# TM4C129XKCZAD register map
Vendor: Texas Instruments; Series: TM4C; File version: 12591
CPU: CM4 r1p2, little endian, no MPU, FPU, 3 interrupt priority bits
Registers are 32-bit, read-write, no defined reset value unless marked. A register's access mark holds for its fields unless they carry their own. Offsets are from the block's base; [hi:lo] are bit positions; {n}, {i} and the like mark numbered series.

## SYSCTL — Register map for SYSCTL peripheral
Base 0x400FE000; register names take the prefix SYSCTL
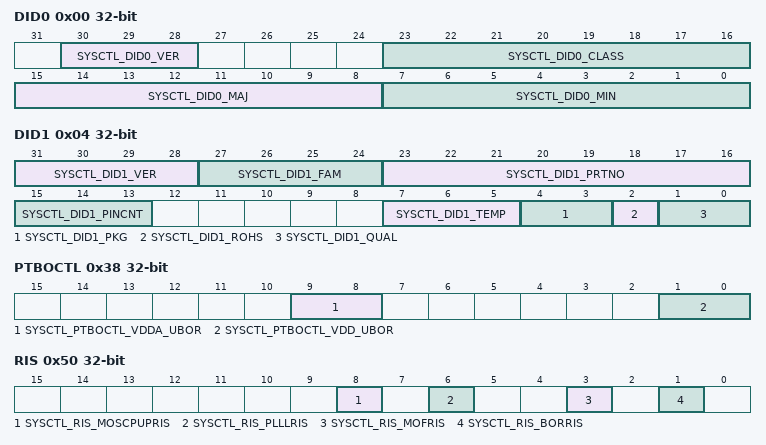
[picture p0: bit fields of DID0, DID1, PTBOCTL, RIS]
0x00 DID0 — Device Identification 0
  [30:28] SYSCTL_DID0_VER — DID0 Version
    1=Second version of the DID0 register format
  [23:16] SYSCTL_DID0_CLASS — Device Class
    10=SYSCTL_DID0_CLASS_TM4C129 (Tiva(TM) TM4C129-class microcontrollers)
  [15:8] SYSCTL_DID0_MAJ — Major Revision
    0=SYSCTL_DID0_MAJ_REVA (Revision A (initial device)); 1=SYSCTL_DID0_MAJ_REVB (Revision B (first base layer revision)); 2=SYSCTL_DID0_MAJ_REVC (Revision C (second base layer revision))
  [7:0] SYSCTL_DID0_MIN — Minor Revision
    0=Initial device, or a major revision update; 1=First metal layer change; 2=Second metal layer change
0x04 DID1 — Device Identification 1
  [31:28] SYSCTL_DID1_VER — DID1 Version
  [27:24] SYSCTL_DID1_FAM — Family
  [23:16] SYSCTL_DID1_PRTNO — Part Number
  [15:13] SYSCTL_DID1_PINCNT — Package Pin Count
    2=100-pin LQFP package; 3=64-pin LQFP package; 4=144-pin LQFP package; 5=157-pin BGA package; 6=128-pin TQFP package
  [7:5] SYSCTL_DID1_TEMP — Temperature Range
    0=SYSCTL_DID1_TEMP_C (Commercial temperature range); 1=SYSCTL_DID1_TEMP_I (Industrial temperature range); 2=SYSCTL_DID1_TEMP_E (Extended temperature range)
  [4:3] SYSCTL_DID1_PKG — Package Type
    1=SYSCTL_DID1_PKG_QFP (QFP package); 2=SYSCTL_DID1_PKG_BGA (BGA package)
  [2] SYSCTL_DID1_ROHS — RoHS-Compliance
  [1:0] SYSCTL_DID1_QUAL — Qualification Status
    0=SYSCTL_DID1_QUAL_ES (Engineering Sample (unqualified)); 1=SYSCTL_DID1_QUAL_PP (Pilot Production (unqualified)); 2=SYSCTL_DID1_QUAL_FQ (Fully Qualified)
0x38 PTBOCTL — Power-Temp Brown Out Control
  [9:8] SYSCTL_PTBOCTL_VDDA_UBOR — VDDA under BOR Event Action
    0=SYSCTL_PTBOCTL_VDDA_UBOR_NONE (No Action); 1=SYSCTL_PTBOCTL_VDDA_UBOR_SYSINT (System control interrupt); 2=SYSCTL_PTBOCTL_VDDA_UBOR_NMI (NMI); 3=SYSCTL_PTBOCTL_VDDA_UBOR_RST (Reset)
  [1:0] SYSCTL_PTBOCTL_VDD_UBOR — VDD (VDDS) under BOR Event Action
    0=SYSCTL_PTBOCTL_VDD_UBOR_NONE (No Action); 1=SYSCTL_PTBOCTL_VDD_UBOR_SYSINT (System control interrupt); 2=SYSCTL_PTBOCTL_VDD_UBOR_NMI (NMI); 3=SYSCTL_PTBOCTL_VDD_UBOR_RST (Reset)
0x50 RIS — Raw Interrupt Status
  [8] SYSCTL_RIS_MOSCPUPRIS — MOSC Power Up Raw Interrupt Status
  [6] SYSCTL_RIS_PLLLRIS — PLL Lock Raw Interrupt Status
  [3] SYSCTL_RIS_MOFRIS — Main Oscillator Failure Raw Interrupt Status
  [1] SYSCTL_RIS_BORRIS — Brown-Out Reset Raw Interrupt Status
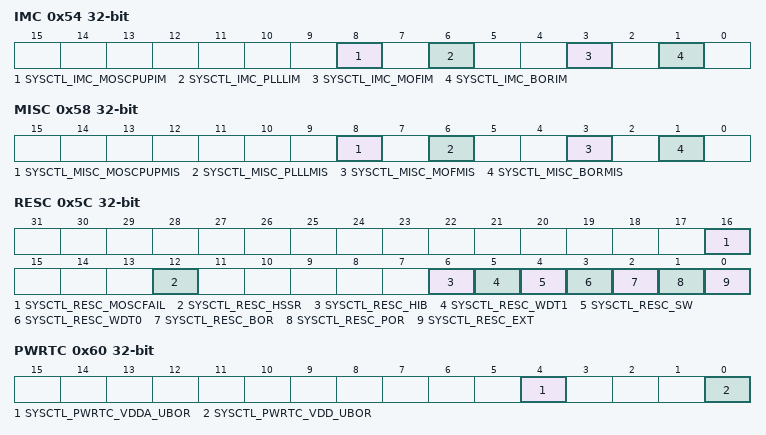
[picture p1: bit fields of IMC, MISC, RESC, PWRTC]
0x54 IMC — Interrupt Mask Control
  [8] SYSCTL_IMC_MOSCPUPIM — MOSC Power Up Interrupt Mask
  [6] SYSCTL_IMC_PLLLIM — PLL Lock Interrupt Mask
  [3] SYSCTL_IMC_MOFIM — Main Oscillator Failure Interrupt Mask
  [1] SYSCTL_IMC_BORIM — Brown-Out Reset Interrupt Mask
0x58 MISC — Masked Interrupt Status and Clear
  [8] SYSCTL_MISC_MOSCPUPMIS — MOSC Power Up Masked Interrupt Status
  [6] SYSCTL_MISC_PLLLMIS — PLL Lock Masked Interrupt Status
  [3] SYSCTL_MISC_MOFMIS — Main Oscillator Failure Masked Interrupt Status
  [1] SYSCTL_MISC_BORMIS — BOR Masked Interrupt Status
0x5C RESC — Reset Cause
  [16] SYSCTL_RESC_MOSCFAIL — MOSC Failure Reset
  [12] SYSCTL_RESC_HSSR — HSSR Reset
  [6] SYSCTL_RESC_HIB — HIB Reset
  [5] SYSCTL_RESC_WDT1 — Watchdog Timer 1 Reset
  [4] SYSCTL_RESC_SW — Software Reset
  [3] SYSCTL_RESC_WDT0 — Watchdog Timer 0 Reset
  [2] SYSCTL_RESC_BOR — Brown-Out Reset
  [1] SYSCTL_RESC_POR — Power-On Reset
  [0] SYSCTL_RESC_EXT — External Reset
0x60 PWRTC — Power-Temperature Cause
  [4] SYSCTL_PWRTC_VDDA_UBOR — VDDA Under BOR Status
  [0] SYSCTL_PWRTC_VDD_UBOR — VDD Under BOR Status
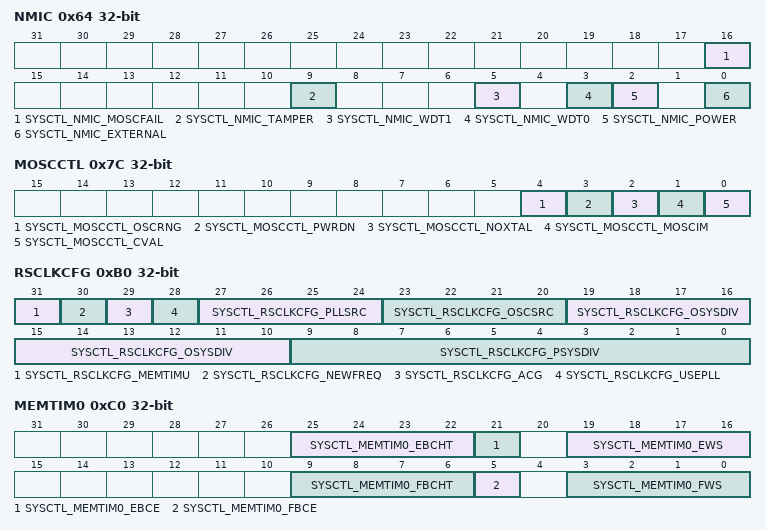
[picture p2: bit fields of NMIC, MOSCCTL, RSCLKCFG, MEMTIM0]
0x64 NMIC — NMI Cause Register
  [16] SYSCTL_NMIC_MOSCFAIL — MOSC Failure NMI
  [9] SYSCTL_NMIC_TAMPER — Tamper Event NMI
  [5] SYSCTL_NMIC_WDT1 — Watch Dog Timer (WDT) 1 NMI
  [3] SYSCTL_NMIC_WDT0 — Watch Dog Timer (WDT) 0 NMI
  [2] SYSCTL_NMIC_POWER — Power/Brown Out Event NMI
  [0] SYSCTL_NMIC_EXTERNAL — External Pin NMI
0x7C MOSCCTL — Main Oscillator Control
  [4] SYSCTL_MOSCCTL_OSCRNG — Oscillator Range
  [3] SYSCTL_MOSCCTL_PWRDN — Power Down
  [2] SYSCTL_MOSCCTL_NOXTAL — No Crystal Connected
  [1] SYSCTL_MOSCCTL_MOSCIM — MOSC Failure Action
  [0] SYSCTL_MOSCCTL_CVAL — Clock Validation for MOSC
0xB0 RSCLKCFG — Run and Sleep Mode Configuration Register
  [31] SYSCTL_RSCLKCFG_MEMTIMU — Memory Timing Register Update
  [30] SYSCTL_RSCLKCFG_NEWFREQ — New PLLFREQ Accept
  [29] SYSCTL_RSCLKCFG_ACG — Auto Clock Gating
  [28] SYSCTL_RSCLKCFG_USEPLL — Use PLL
  [27:24] SYSCTL_RSCLKCFG_PLLSRC — PLL Source
    0=SYSCTL_RSCLKCFG_PLLSRC_PIOSC (PIOSC is PLL input clock source); 3=SYSCTL_RSCLKCFG_PLLSRC_MOSC (MOSC is the PLL input clock source)
  [23:20] SYSCTL_RSCLKCFG_OSCSRC — Oscillator Source
    0=SYSCTL_RSCLKCFG_OSCSRC_PIOSC (PIOSC is oscillator source); 2=SYSCTL_RSCLKCFG_OSCSRC_LFIOSC (LFIOSC is oscillator source); 3=SYSCTL_RSCLKCFG_OSCSRC_MOSC (MOSC is oscillator source); 4=SYSCTL_RSCLKCFG_OSCSRC_RTC (Hibernation Module RTC Oscillator (RTCOSC))
  [19:10] SYSCTL_RSCLKCFG_OSYSDIV — Oscillator System Clock Divisor
  [9:0] SYSCTL_RSCLKCFG_PSYSDIV — PLL System Clock Divisor
0xC0 MEMTIM0 — Memory Timing Parameter Register 0 for Main Flash and EEPROM
  [25:22] SYSCTL_MEMTIM0_EBCHT — EEPROM Clock High Time
    0=SYSCTL_MEMTIM0_EBCHT_0_5 (1/2 system clock period); 1=1 system clock period; 2=SYSCTL_MEMTIM0_EBCHT_1_5 (1.5 system clock periods); 3=2 system clock periods; 4=SYSCTL_MEMTIM0_EBCHT_2_5 (2.5 system clock periods); 5=3 system clock periods; 6=SYSCTL_MEMTIM0_EBCHT_3_5 (3.5 system clock periods); 7=4 system clock periods; 8=SYSCTL_MEMTIM0_EBCHT_4_5 (4.5 system clock periods)
  [21] SYSCTL_MEMTIM0_EBCE — EEPROM Bank Clock Edge
  [19:16] SYSCTL_MEMTIM0_EWS — EEPROM Wait States
  [9:6] SYSCTL_MEMTIM0_FBCHT — Flash Bank Clock High Time
    0=SYSCTL_MEMTIM0_FBCHT_0_5 (1/2 system clock period); 1=1 system clock period; 2=SYSCTL_MEMTIM0_FBCHT_1_5 (1.5 system clock periods); 3=2 system clock periods; 4=SYSCTL_MEMTIM0_FBCHT_2_5 (2.5 system clock periods); 5=3 system clock periods; 6=SYSCTL_MEMTIM0_FBCHT_3_5 (3.5 system clock periods); 7=4 system clock periods; 8=SYSCTL_MEMTIM0_FBCHT_4_5 (4.5 system clock periods)
  [5] SYSCTL_MEMTIM0_FBCE — Flash Bank Clock Edge
  [3:0] SYSCTL_MEMTIM0_FWS — Flash Wait State
0x138 ALTCLKCFG — Alternate Clock Configuration
  [3:0] SYSCTL_ALTCLKCFG_ALTCLK — Alternate Clock Source
    0=SYSCTL_ALTCLKCFG_ALTCLK_PIOSC (PIOSC); 3=SYSCTL_ALTCLKCFG_ALTCLK_RTCOSC (Hibernation Module Real-time clock output (RTCOSC)); 4=SYSCTL_ALTCLKCFG_ALTCLK_LFIOSC (Low-frequency internal oscillator (LFIOSC))
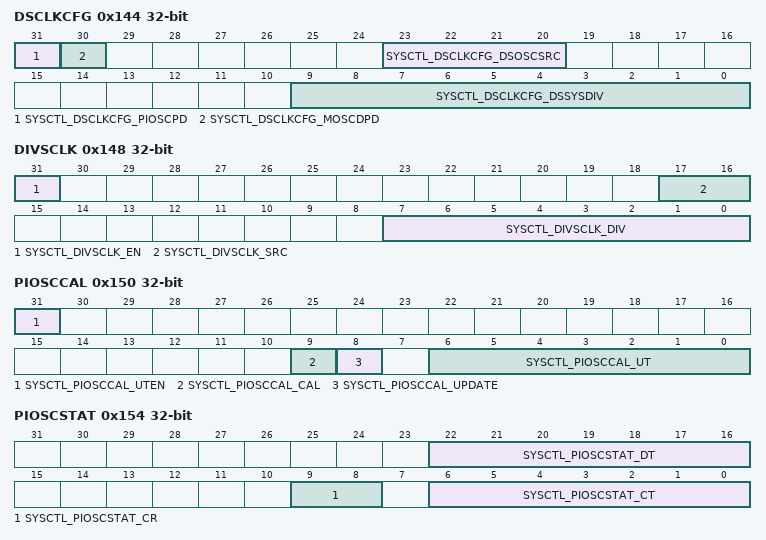
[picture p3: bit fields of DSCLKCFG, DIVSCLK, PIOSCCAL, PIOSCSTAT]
0x144 DSCLKCFG — Deep Sleep Clock Configuration Register
  [31] SYSCTL_DSCLKCFG_PIOSCPD — PIOSC Power Down
  [30] SYSCTL_DSCLKCFG_MOSCDPD — MOSC Disable Power Down
  [23:20] SYSCTL_DSCLKCFG_DSOSCSRC — Deep Sleep Oscillator Source
    0=SYSCTL_DSCLKCFG_DSOSCSRC_PIOSC (PIOSC); 2=SYSCTL_DSCLKCFG_DSOSCSRC_LFIOSC (LFIOSC); 3=SYSCTL_DSCLKCFG_DSOSCSRC_MOSC (MOSC); 4=SYSCTL_DSCLKCFG_DSOSCSRC_RTC (Hibernation Module RTCOSC)
  [9:0] SYSCTL_DSCLKCFG_DSSYSDIV — Deep Sleep Clock Divisor
0x148 DIVSCLK — Divisor and Source Clock Configuration
  [31] SYSCTL_DIVSCLK_EN — DIVSCLK Enable
  [17:16] SYSCTL_DIVSCLK_SRC — Clock Source
    0=SYSCTL_DIVSCLK_SRC_SYSCLK (System Clock); 1=SYSCTL_DIVSCLK_SRC_PIOSC (PIOSC); 2=SYSCTL_DIVSCLK_SRC_MOSC (MOSC)
  [7:0] SYSCTL_DIVSCLK_DIV — Divisor Value
0x14C SYSPROP — System Properties
  [0] SYSCTL_SYSPROP_FPU — FPU Present
0x150 PIOSCCAL — Precision Internal Oscillator Calibration
  [31] SYSCTL_PIOSCCAL_UTEN — Use User Trim Value
  [9] SYSCTL_PIOSCCAL_CAL — Start Calibration
  [8] SYSCTL_PIOSCCAL_UPDATE — Update Trim
  [6:0] SYSCTL_PIOSCCAL_UT — User Trim Value
0x154 PIOSCSTAT — Precision Internal Oscillator Statistics
  [22:16] SYSCTL_PIOSCSTAT_DT — Default Trim Value
  [9:8] SYSCTL_PIOSCSTAT_CR — Calibration Result
    0=SYSCTL_PIOSCSTAT_CRNONE (Calibration has not been attempted); 1=SYSCTL_PIOSCSTAT_CRPASS (The last calibration operation completed to meet 1% accuracy); 2=SYSCTL_PIOSCSTAT_CRFAIL (The last calibration operation failed to meet 1% accuracy)
  [6:0] SYSCTL_PIOSCSTAT_CT — Calibration Trim Value
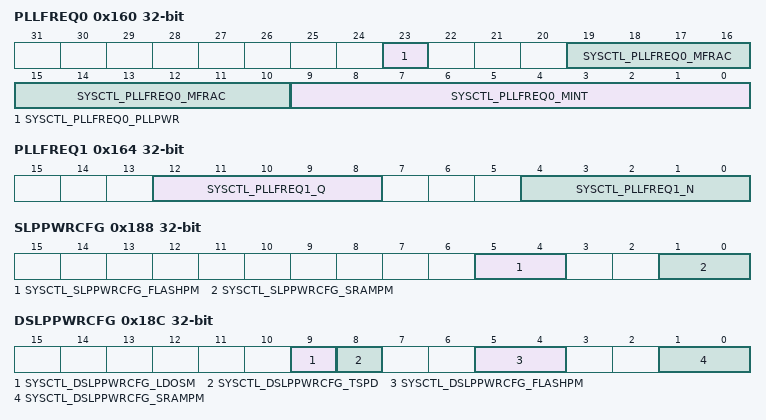
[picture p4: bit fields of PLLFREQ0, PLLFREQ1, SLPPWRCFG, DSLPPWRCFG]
0x160 PLLFREQ0 — PLL Frequency 0
  [23] SYSCTL_PLLFREQ0_PLLPWR — PLL Power
  [19:10] SYSCTL_PLLFREQ0_MFRAC — PLL M Fractional Value
  [9:0] SYSCTL_PLLFREQ0_MINT — PLL M Integer Value
0x164 PLLFREQ1 — PLL Frequency 1
  [12:8] SYSCTL_PLLFREQ1_Q — PLL Q Value
  [4:0] SYSCTL_PLLFREQ1_N — PLL N Value
0x168 PLLSTAT — PLL Status
  [0] SYSCTL_PLLSTAT_LOCK — PLL Lock
0x188 SLPPWRCFG — Sleep Power Configuration
  [5:4] SYSCTL_SLPPWRCFG_FLASHPM — Flash Power Modes
    0=SYSCTL_SLPPWRCFG_FLASHPM_NRM (Active Mode); 2=SYSCTL_SLPPWRCFG_FLASHPM_SLP (Low Power Mode)
  [1:0] SYSCTL_SLPPWRCFG_SRAMPM — SRAM Power Modes
    0=SYSCTL_SLPPWRCFG_SRAMPM_NRM (Active Mode); 1=SYSCTL_SLPPWRCFG_SRAMPM_SBY (Standby Mode); 3=SYSCTL_SLPPWRCFG_SRAMPM_LP (Low Power Mode)
0x18C DSLPPWRCFG — Deep-Sleep Power Configuration
  [9] SYSCTL_DSLPPWRCFG_LDOSM — LDO Sleep Mode
  [8] SYSCTL_DSLPPWRCFG_TSPD — Temperature Sense Power Down
  [5:4] SYSCTL_DSLPPWRCFG_FLASHPM — Flash Power Modes
    0=SYSCTL_DSLPPWRCFG_FLASHPM_NRM (Active Mode); 2=SYSCTL_DSLPPWRCFG_FLASHPM_SLP (Low Power Mode)
  [1:0] SYSCTL_DSLPPWRCFG_SRAMPM — SRAM Power Modes
    0=SYSCTL_DSLPPWRCFG_SRAMPM_NRM (Active Mode); 1=SYSCTL_DSLPPWRCFG_SRAMPM_SBY (Standby Mode); 3=SYSCTL_DSLPPWRCFG_SRAMPM_LP (Low Power Mode)
0x1A0 NVMSTAT — Non-Volatile Memory Information
  [0] SYSCTL_NVMSTAT_FWB — 32 Word Flash Write Buffer Available
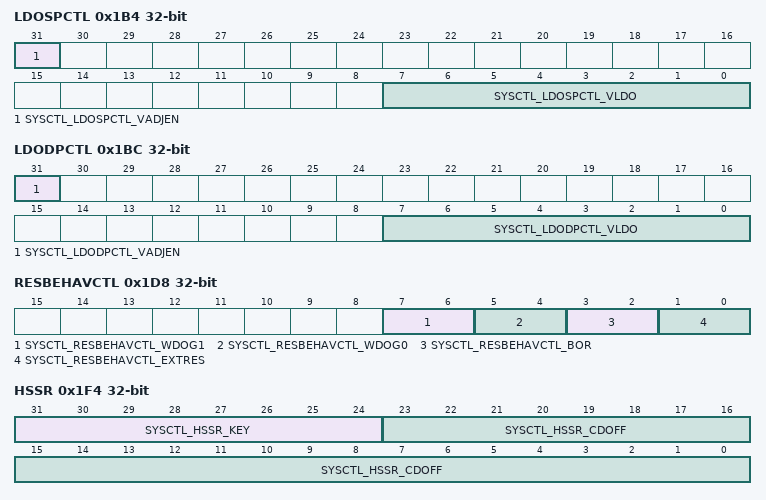
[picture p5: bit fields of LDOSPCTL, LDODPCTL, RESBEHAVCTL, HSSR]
0x1B4 LDOSPCTL — LDO Sleep Power Control
  [31] SYSCTL_LDOSPCTL_VADJEN — Voltage Adjust Enable
  [7:0] SYSCTL_LDOSPCTL_VLDO — LDO Output Voltage
    18=SYSCTL_LDOSPCTL_VLDO_0_90V (0.90 V); 19=SYSCTL_LDOSPCTL_VLDO_0_95V (0.95 V); 20=SYSCTL_LDOSPCTL_VLDO_1_00V (1.00 V); 21=SYSCTL_LDOSPCTL_VLDO_1_05V (1.05 V); 22=SYSCTL_LDOSPCTL_VLDO_1_10V (1.10 V); 23=SYSCTL_LDOSPCTL_VLDO_1_15V (1.15 V); 24=SYSCTL_LDOSPCTL_VLDO_1_20V (1.20 V)
0x1BC LDODPCTL — LDO Deep-Sleep Power Control
  [31] SYSCTL_LDODPCTL_VADJEN — Voltage Adjust Enable
  [7:0] SYSCTL_LDODPCTL_VLDO — LDO Output Voltage
    18=SYSCTL_LDODPCTL_VLDO_0_90V (0.90 V); 19=SYSCTL_LDODPCTL_VLDO_0_95V (0.95 V); 20=SYSCTL_LDODPCTL_VLDO_1_00V (1.00 V); 21=SYSCTL_LDODPCTL_VLDO_1_05V (1.05 V); 22=SYSCTL_LDODPCTL_VLDO_1_10V (1.10 V); 23=SYSCTL_LDODPCTL_VLDO_1_15V (1.15 V); 24=SYSCTL_LDODPCTL_VLDO_1_20V (1.20 V); 25=SYSCTL_LDODPCTL_VLDO_1_25V (1.25 V); 26=SYSCTL_LDODPCTL_VLDO_1_30V (1.30 V); 27=SYSCTL_LDODPCTL_VLDO_1_35V (1.35 V)
0x1D8 RESBEHAVCTL — Reset Behavior Control Register
  [7:6] SYSCTL_RESBEHAVCTL_WDOG1 — Watchdog 1 Reset Operation
    2=SYSCTL_RESBEHAVCTL_WDOG1_SYSRST (Watchdog 1 issues a system reset. The application starts within 10 us); 3=SYSCTL_RESBEHAVCTL_WDOG1_POR (Watchdog 1 issues a simulated POR sequence. Application starts less than 500 us after deassertion (Default))
  [5:4] SYSCTL_RESBEHAVCTL_WDOG0 — Watchdog 0 Reset Operation
    2=SYSCTL_RESBEHAVCTL_WDOG0_SYSRST (Watchdog 0 issues a system reset. The application starts within 10 us); 3=SYSCTL_RESBEHAVCTL_WDOG0_POR (Watchdog 0 issues a simulated POR sequence. Application starts less than 500 us after deassertion (Default))
  [3:2] SYSCTL_RESBEHAVCTL_BOR — BOR Reset operation
    2=SYSCTL_RESBEHAVCTL_BOR_SYSRST (Brown Out Reset issues system reset. The application starts within 10 us); 3=SYSCTL_RESBEHAVCTL_BOR_POR (Brown Out Reset issues a simulated POR sequence. The application starts less than 500 us after deassertion (Default))
  [1:0] SYSCTL_RESBEHAVCTL_EXTRES — External RST Pin Operation
    2=SYSCTL_RESBEHAVCTL_EXTRES_SYSRST (External RST assertion issues a system reset. The application starts within 10 us); 3=SYSCTL_RESBEHAVCTL_EXTRES_POR (External RST assertion issues a simulated POR sequence. Application starts less than 500 us after deassertion (Default))
0x1F4 HSSR — Hardware System Service Request
  [31:24] SYSCTL_HSSR_KEY — Write Key
  [23:0] SYSCTL_HSSR_CDOFF — Command Descriptor Pointer
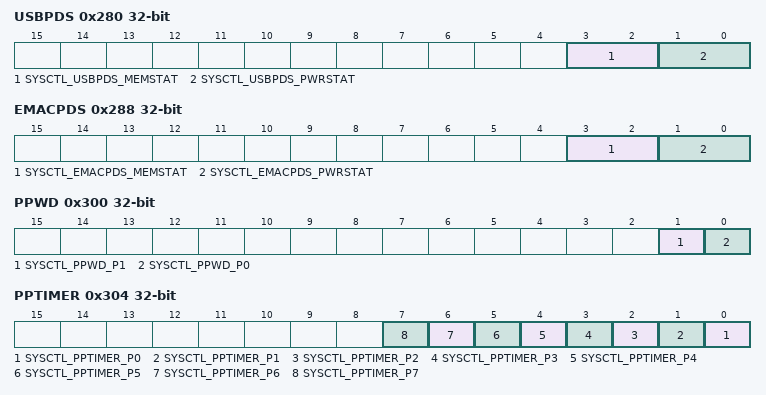
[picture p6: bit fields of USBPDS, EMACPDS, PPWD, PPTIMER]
0x280 USBPDS — USB Power Domain Status
  [3:2] SYSCTL_USBPDS_MEMSTAT — Memory Array Power Status
    0=SYSCTL_USBPDS_MEMSTAT_OFF (Array OFF); 1=SYSCTL_USBPDS_MEMSTAT_RETAIN (SRAM Retention); 3=SYSCTL_USBPDS_MEMSTAT_ON (Array On)
  [1:0] SYSCTL_USBPDS_PWRSTAT — Power Domain Status
    0=SYSCTL_USBPDS_PWRSTAT_OFF (OFF); 3=SYSCTL_USBPDS_PWRSTAT_ON (ON)
0x284 USBMPC — USB Memory Power Control
  [1:0] SYSCTL_USBMPC_PWRCTL — Memory Array Power Control
    0=SYSCTL_USBMPC_PWRCTL_OFF (Array OFF); 1=SYSCTL_USBMPC_PWRCTL_RETAIN (SRAM Retention); 3=SYSCTL_USBMPC_PWRCTL_ON (Array On)
0x288 EMACPDS — Ethernet MAC Power Domain Status
  [3:2] SYSCTL_EMACPDS_MEMSTAT — Memory Array Power Status
    0=SYSCTL_EMACPDS_MEMSTAT_OFF (Array OFF); 3=SYSCTL_EMACPDS_MEMSTAT_ON (Array On)
  [1:0] SYSCTL_EMACPDS_PWRSTAT — Power Domain Status
    0=SYSCTL_EMACPDS_PWRSTAT_OFF (OFF); 3=SYSCTL_EMACPDS_PWRSTAT_ON (ON)
0x28C EMACMPC — Ethernet MAC Memory Power Control
  [1:0] SYSCTL_EMACMPC_PWRCTL — Memory Array Power Control
    0=SYSCTL_EMACMPC_PWRCTL_OFF (Array OFF); 3=SYSCTL_EMACMPC_PWRCTL_ON (Array On)
0x294 LCDMPC — LCD Memory Power Control
  [1:0] SYSCTL_LCDMPC_PWRCTL — Memory Array Power Control
    0=SYSCTL_LCDMPC_PWRCTL_OFF (Array OFF); 3=SYSCTL_LCDMPC_PWRCTL_ON (Array On)
0x300 PPWD — Watchdog Timer Peripheral Present
  [1] SYSCTL_PPWD_P1 — Watchdog Timer 1 Present
  [0] SYSCTL_PPWD_P0 — Watchdog Timer 0 Present
0x304 PPTIMER — 16/32-Bit General-Purpose Timer Peripheral Present
  [n] SYSCTL_PPTIMER_P{n} (n=0..7) — 16/32-Bit General-Purpose Timer {n} Present
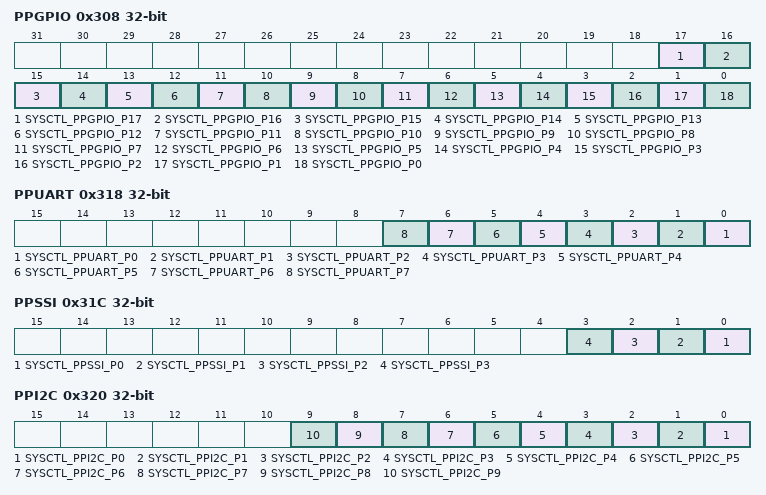
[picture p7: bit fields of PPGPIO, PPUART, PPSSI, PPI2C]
0x308 PPGPIO — General-Purpose Input/Output Peripheral Present
  [17] SYSCTL_PPGPIO_P17 — GPIO Port T Present
  [16] SYSCTL_PPGPIO_P16 — GPIO Port S Present
  [15] SYSCTL_PPGPIO_P15 — GPIO Port R Present
  [14] SYSCTL_PPGPIO_P14 — GPIO Port Q Present
  [13] SYSCTL_PPGPIO_P13 — GPIO Port P Present
  [12] SYSCTL_PPGPIO_P12 — GPIO Port N Present
  [11] SYSCTL_PPGPIO_P11 — GPIO Port M Present
  [10] SYSCTL_PPGPIO_P10 — GPIO Port L Present
  [9] SYSCTL_PPGPIO_P9 — GPIO Port K Present
  [8] SYSCTL_PPGPIO_P8 — GPIO Port J Present
  [7] SYSCTL_PPGPIO_P7 — GPIO Port H Present
  [6] SYSCTL_PPGPIO_P6 — GPIO Port G Present
  [5] SYSCTL_PPGPIO_P5 — GPIO Port F Present
  [4] SYSCTL_PPGPIO_P4 — GPIO Port E Present
  [3] SYSCTL_PPGPIO_P3 — GPIO Port D Present
  [2] SYSCTL_PPGPIO_P2 — GPIO Port C Present
  [1] SYSCTL_PPGPIO_P1 — GPIO Port B Present
  [0] SYSCTL_PPGPIO_P0 — GPIO Port A Present
0x30C PPDMA — Micro Direct Memory Access Peripheral Present
  [0] SYSCTL_PPDMA_P0 — uDMA Module Present
0x310 PPEPI — EPI Peripheral Present
  [0] SYSCTL_PPEPI_P0 — EPI Module Present
0x314 PPHIB — Hibernation Peripheral Present
  [0] SYSCTL_PPHIB_P0 — Hibernation Module Present
0x318 PPUART — Universal Asynchronous Receiver/Transmitter Peripheral Present
  [n] SYSCTL_PPUART_P{n} (n=0..7) — UART Module {n} Present
0x31C PPSSI — Synchronous Serial Interface Peripheral Present
  [n] SYSCTL_PPSSI_P{n} (n=0..3) — SSI Module {n} Present
0x320 PPI2C — Inter-Integrated Circuit Peripheral Present
  [n] SYSCTL_PPI2C_P{n} (n=0..9) — I2C Module {n} Present
0x328 PPUSB — Universal Serial Bus Peripheral Present
  [0] SYSCTL_PPUSB_P0 — USB Module Present
0x330 PPEPHY — Ethernet PHY Peripheral Present
  [0] SYSCTL_PPEPHY_P0 — Ethernet PHY Module Present
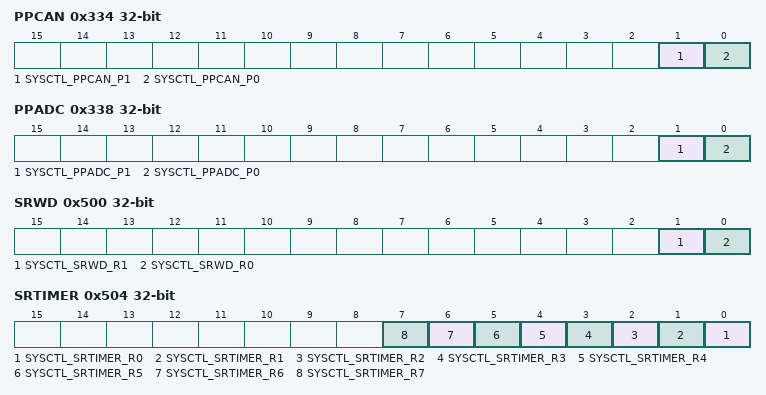
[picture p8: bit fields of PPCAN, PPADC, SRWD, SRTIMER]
0x334 PPCAN — Controller Area Network Peripheral Present
  [1] SYSCTL_PPCAN_P1 — CAN Module 1 Present
  [0] SYSCTL_PPCAN_P0 — CAN Module 0 Present
0x338 PPADC — Analog-to-Digital Converter Peripheral Present
  [1] SYSCTL_PPADC_P1 — ADC Module 1 Present
  [0] SYSCTL_PPADC_P0 — ADC Module 0 Present
0x33C PPACMP — Analog Comparator Peripheral Present
  [0] SYSCTL_PPACMP_P0 — Analog Comparator Module Present
0x340 PPPWM — Pulse Width Modulator Peripheral Present
  [0] SYSCTL_PPPWM_P0 — PWM Module 0 Present
0x344 PPQEI — Quadrature Encoder Interface Peripheral Present
  [0] SYSCTL_PPQEI_P0 — QEI Module 0 Present
0x348 PPLPC — Low Pin Count Interface Peripheral Present
  [0] SYSCTL_PPLPC_P0 — LPC Module Present
0x350 PPPECI — Platform Environment Control Interface Peripheral Present
  [0] SYSCTL_PPPECI_P0 — PECI Module Present
0x354 PPFAN — Fan Control Peripheral Present
  [0] SYSCTL_PPFAN_P0 — FAN Module 0 Present
0x358 PPEEPROM — EEPROM Peripheral Present
  [0] SYSCTL_PPEEPROM_P0 — EEPROM Module Present
0x35C PPWTIMER — 32/64-Bit Wide General-Purpose Timer Peripheral Present
  [0] SYSCTL_PPWTIMER_P0 — 32/64-Bit Wide General-Purpose Timer 0 Present
0x370 PPRTS — Remote Temperature Sensor Peripheral Present
  [0] SYSCTL_PPRTS_P0 — RTS Module Present
0x374 PPCCM — CRC and Cryptographic Modules Peripheral Present
  [0] SYSCTL_PPCCM_P0 — CRC and Cryptographic Modules Present
0x390 PPLCD — LCD Peripheral Present
  [0] SYSCTL_PPLCD_P0 — LCD Module Present
0x398 PPOWIRE — 1-Wire Peripheral Present
  [0] SYSCTL_PPOWIRE_P0 — 1-Wire Module Present
0x39C PPEMAC — Ethernet MAC Peripheral Present
  [0] SYSCTL_PPEMAC_P0 — Ethernet Controller Module Present
0x3A4 PPHIM — Human Interface Master Peripheral Present
  [0] SYSCTL_PPHIM_P0 — HIM Module Present
0x500 SRWD — Watchdog Timer Software Reset
  [1] SYSCTL_SRWD_R1 — Watchdog Timer 1 Software Reset
  [0] SYSCTL_SRWD_R0 — Watchdog Timer 0 Software Reset
0x504 SRTIMER — 16/32-Bit General-Purpose Timer Software Reset
  [n] SYSCTL_SRTIMER_R{n} (n=0..7) — 16/32-Bit General-Purpose Timer {n} Software Reset
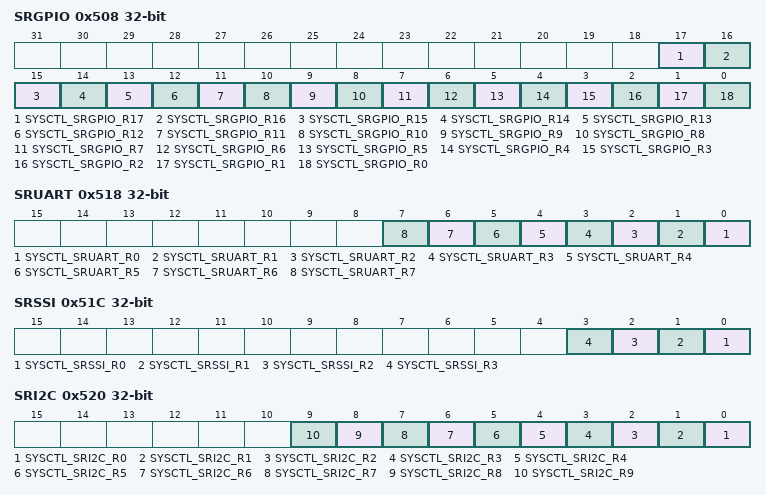
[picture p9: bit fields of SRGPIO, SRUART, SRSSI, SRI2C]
0x508 SRGPIO — General-Purpose Input/Output Software Reset
  [17] SYSCTL_SRGPIO_R17 — GPIO Port T Software Reset
  [16] SYSCTL_SRGPIO_R16 — GPIO Port S Software Reset
  [15] SYSCTL_SRGPIO_R15 — GPIO Port R Software Reset
  [14] SYSCTL_SRGPIO_R14 — GPIO Port Q Software Reset
  [13] SYSCTL_SRGPIO_R13 — GPIO Port P Software Reset
  [12] SYSCTL_SRGPIO_R12 — GPIO Port N Software Reset
  [11] SYSCTL_SRGPIO_R11 — GPIO Port M Software Reset
  [10] SYSCTL_SRGPIO_R10 — GPIO Port L Software Reset
  [9] SYSCTL_SRGPIO_R9 — GPIO Port K Software Reset
  [8] SYSCTL_SRGPIO_R8 — GPIO Port J Software Reset
  [7] SYSCTL_SRGPIO_R7 — GPIO Port H Software Reset
  [6] SYSCTL_SRGPIO_R6 — GPIO Port G Software Reset
  [5] SYSCTL_SRGPIO_R5 — GPIO Port F Software Reset
  [4] SYSCTL_SRGPIO_R4 — GPIO Port E Software Reset
  [3] SYSCTL_SRGPIO_R3 — GPIO Port D Software Reset
  [2] SYSCTL_SRGPIO_R2 — GPIO Port C Software Reset
  [1] SYSCTL_SRGPIO_R1 — GPIO Port B Software Reset
  [0] SYSCTL_SRGPIO_R0 — GPIO Port A Software Reset
0x50C SRDMA — Micro Direct Memory Access Software Reset
  [0] SYSCTL_SRDMA_R0 — uDMA Module Software Reset
0x510 SREPI — EPI Software Reset
  [0] SYSCTL_SREPI_R0 — EPI Module Software Reset
0x514 SRHIB — Hibernation Software Reset
  [0] SYSCTL_SRHIB_R0 — Hibernation Module Software Reset
0x518 SRUART — Universal Asynchronous Receiver/Transmitter Software Reset
  [n] SYSCTL_SRUART_R{n} (n=0..7) — UART Module {n} Software Reset
0x51C SRSSI — Synchronous Serial Interface Software Reset
  [n] SYSCTL_SRSSI_R{n} (n=0..3) — SSI Module {n} Software Reset
0x520 SRI2C — Inter-Integrated Circuit Software Reset
  [n] SYSCTL_SRI2C_R{n} (n=0..9) — I2C Module {n} Software Reset
0x528 SRUSB — Universal Serial Bus Software Reset
  [0] SYSCTL_SRUSB_R0 — USB Module Software Reset
0x530 SREPHY — Ethernet PHY Software Reset
  [0] SYSCTL_SREPHY_R0 — Ethernet PHY Module Software Reset
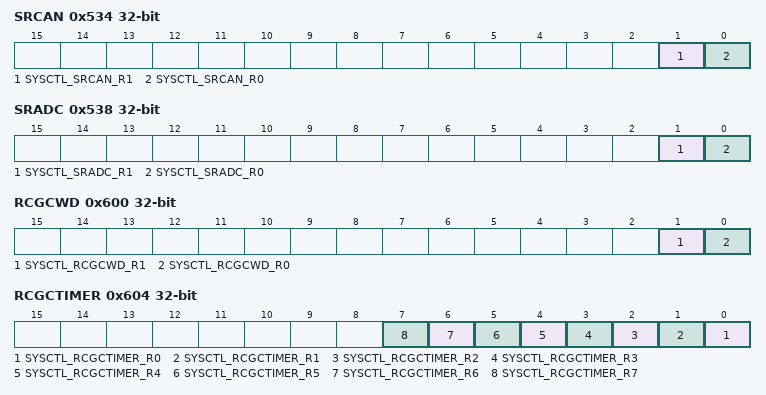
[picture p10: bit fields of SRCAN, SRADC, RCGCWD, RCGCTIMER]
0x534 SRCAN — Controller Area Network Software Reset
  [1] SYSCTL_SRCAN_R1 — CAN Module 1 Software Reset
  [0] SYSCTL_SRCAN_R0 — CAN Module 0 Software Reset
0x538 SRADC — Analog-to-Digital Converter Software Reset
  [1] SYSCTL_SRADC_R1 — ADC Module 1 Software Reset
  [0] SYSCTL_SRADC_R0 — ADC Module 0 Software Reset
0x53C SRACMP — Analog Comparator Software Reset
  [0] SYSCTL_SRACMP_R0 — Analog Comparator Module 0 Software Reset
0x540 SRPWM — Pulse Width Modulator Software Reset
  [0] SYSCTL_SRPWM_R0 — PWM Module 0 Software Reset
0x544 SRQEI — Quadrature Encoder Interface Software Reset
  [0] SYSCTL_SRQEI_R0 — QEI Module 0 Software Reset
0x558 SREEPROM — EEPROM Software Reset
  [0] SYSCTL_SREEPROM_R0 — EEPROM Module Software Reset
0x574 SRCCM — CRC and Cryptographic Modules Software Reset
  [0] SYSCTL_SRCCM_R0
0x590 SRLCD — LCD Controller Software Reset
  [0] SYSCTL_SRLCD_R0 — LCD Module 0 Software Reset
0x598 SROWIRE — 1-Wire Software Reset
  [0] SYSCTL_SROWIRE_R0 — 1-Wire Module Software Reset
0x59C SREMAC — Ethernet MAC Software Reset
  [0] SYSCTL_SREMAC_R0 — Ethernet Controller MAC Module 0 Software Reset
0x600 RCGCWD — Watchdog Timer Run Mode Clock Gating Control
  [1] SYSCTL_RCGCWD_R1 — Watchdog Timer 1 Run Mode Clock Gating Control
  [0] SYSCTL_RCGCWD_R0 — Watchdog Timer 0 Run Mode Clock Gating Control
0x604 RCGCTIMER — 16/32-Bit General-Purpose Timer Run Mode Clock Gating Control
  [n] SYSCTL_RCGCTIMER_R{n} (n=0..7) — 16/32-Bit General-Purpose Timer {n} Run Mode Clock Gating Control
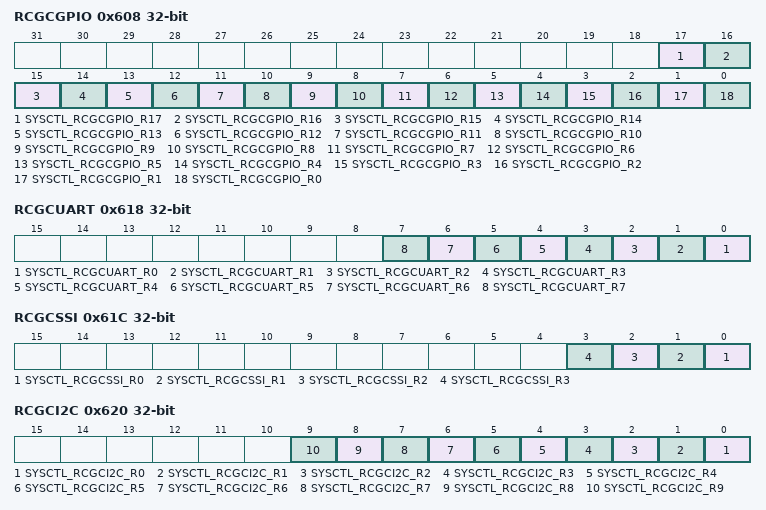
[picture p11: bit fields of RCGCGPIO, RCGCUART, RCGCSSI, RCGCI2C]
0x608 RCGCGPIO — General-Purpose Input/Output Run Mode Clock Gating Control
  [17] SYSCTL_RCGCGPIO_R17 — GPIO Port T Run Mode Clock Gating Control
  [16] SYSCTL_RCGCGPIO_R16 — GPIO Port S Run Mode Clock Gating Control
  [15] SYSCTL_RCGCGPIO_R15 — GPIO Port R Run Mode Clock Gating Control
  [14] SYSCTL_RCGCGPIO_R14 — GPIO Port Q Run Mode Clock Gating Control
  [13] SYSCTL_RCGCGPIO_R13 — GPIO Port P Run Mode Clock Gating Control
  [12] SYSCTL_RCGCGPIO_R12 — GPIO Port N Run Mode Clock Gating Control
  [11] SYSCTL_RCGCGPIO_R11 — GPIO Port M Run Mode Clock Gating Control
  [10] SYSCTL_RCGCGPIO_R10 — GPIO Port L Run Mode Clock Gating Control
  [9] SYSCTL_RCGCGPIO_R9 — GPIO Port K Run Mode Clock Gating Control
  [8] SYSCTL_RCGCGPIO_R8 — GPIO Port J Run Mode Clock Gating Control
  [7] SYSCTL_RCGCGPIO_R7 — GPIO Port H Run Mode Clock Gating Control
  [6] SYSCTL_RCGCGPIO_R6 — GPIO Port G Run Mode Clock Gating Control
  [5] SYSCTL_RCGCGPIO_R5 — GPIO Port F Run Mode Clock Gating Control
  [4] SYSCTL_RCGCGPIO_R4 — GPIO Port E Run Mode Clock Gating Control
  [3] SYSCTL_RCGCGPIO_R3 — GPIO Port D Run Mode Clock Gating Control
  [2] SYSCTL_RCGCGPIO_R2 — GPIO Port C Run Mode Clock Gating Control
  [1] SYSCTL_RCGCGPIO_R1 — GPIO Port B Run Mode Clock Gating Control
  [0] SYSCTL_RCGCGPIO_R0 — GPIO Port A Run Mode Clock Gating Control
0x60C RCGCDMA — Micro Direct Memory Access Run Mode Clock Gating Control
  [0] SYSCTL_RCGCDMA_R0 — uDMA Module Run Mode Clock Gating Control
0x610 RCGCEPI — EPI Run Mode Clock Gating Control
  [0] SYSCTL_RCGCEPI_R0 — EPI Module Run Mode Clock Gating Control
0x614 RCGCHIB — Hibernation Run Mode Clock Gating Control
  [0] SYSCTL_RCGCHIB_R0 — Hibernation Module Run Mode Clock Gating Control
0x618 RCGCUART — Universal Asynchronous Receiver/Transmitter Run Mode Clock Gating Control
  [n] SYSCTL_RCGCUART_R{n} (n=0..7) — UART Module {n} Run Mode Clock Gating Control
0x61C RCGCSSI — Synchronous Serial Interface Run Mode Clock Gating Control
  [n] SYSCTL_RCGCSSI_R{n} (n=0..3) — SSI Module {n} Run Mode Clock Gating Control
0x620 RCGCI2C — Inter-Integrated Circuit Run Mode Clock Gating Control
  [n] SYSCTL_RCGCI2C_R{n} (n=0..9) — I2C Module {n} Run Mode Clock Gating Control
0x628 RCGCUSB — Universal Serial Bus Run Mode Clock Gating Control
  [0] SYSCTL_RCGCUSB_R0 — USB Module Run Mode Clock Gating Control
0x630 RCGCEPHY — Ethernet PHY Run Mode Clock Gating Control
  [0] SYSCTL_RCGCEPHY_R0 — Ethernet PHY Module Run Mode Clock Gating Control
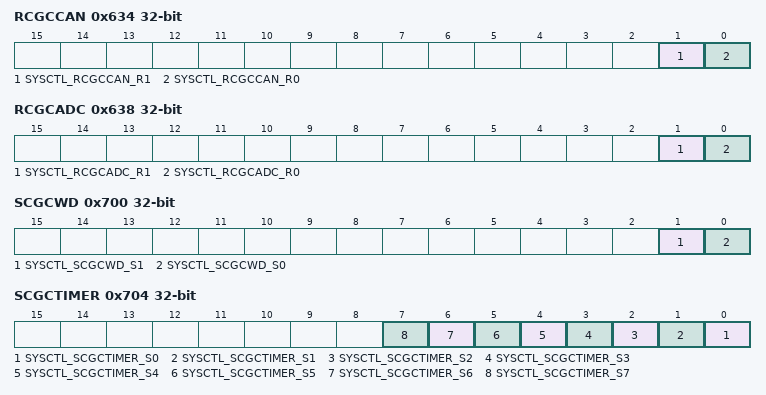
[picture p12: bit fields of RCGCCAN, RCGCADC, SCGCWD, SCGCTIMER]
0x634 RCGCCAN — Controller Area Network Run Mode Clock Gating Control
  [1] SYSCTL_RCGCCAN_R1 — CAN Module 1 Run Mode Clock Gating Control
  [0] SYSCTL_RCGCCAN_R0 — CAN Module 0 Run Mode Clock Gating Control
0x638 RCGCADC — Analog-to-Digital Converter Run Mode Clock Gating Control
  [1] SYSCTL_RCGCADC_R1 — ADC Module 1 Run Mode Clock Gating Control
  [0] SYSCTL_RCGCADC_R0 — ADC Module 0 Run Mode Clock Gating Control
0x63C RCGCACMP — Analog Comparator Run Mode Clock Gating Control
  [0] SYSCTL_RCGCACMP_R0 — Analog Comparator Module 0 Run Mode Clock Gating Control
0x640 RCGCPWM — Pulse Width Modulator Run Mode Clock Gating Control
  [0] SYSCTL_RCGCPWM_R0 — PWM Module 0 Run Mode Clock Gating Control
0x644 RCGCQEI — Quadrature Encoder Interface Run Mode Clock Gating Control
  [0] SYSCTL_RCGCQEI_R0 — QEI Module 0 Run Mode Clock Gating Control
0x658 RCGCEEPROM — EEPROM Run Mode Clock Gating Control
  [0] SYSCTL_RCGCEEPROM_R0 — EEPROM Module Run Mode Clock Gating Control
0x674 RCGCCCM — CRC and Cryptographic Modules Run Mode Clock Gating Control
  [0] SYSCTL_RCGCCCM_R0
0x690 RCGCLCD — LCD Controller Run Mode Clock Gating Control
  [0] SYSCTL_RCGCLCD_R0 — LCD Controller Module 0 Run Mode Clock Gating Control
0x698 RCGCOWIRE — 1-Wire Run Mode Clock Gating Control
  [0] SYSCTL_RCGCOWIRE_R0 — 1-Wire Module 0 Run Mode Clock Gating Control
0x69C RCGCEMAC — Ethernet MAC Run Mode Clock Gating Control
  [0] SYSCTL_RCGCEMAC_R0 — Ethernet MAC Module 0 Run Mode Clock Gating Control
0x700 SCGCWD — Watchdog Timer Sleep Mode Clock Gating Control
  [1] SYSCTL_SCGCWD_S1 — Watchdog Timer 1 Sleep Mode Clock Gating Control
  [0] SYSCTL_SCGCWD_S0 — Watchdog Timer 0 Sleep Mode Clock Gating Control
0x704 SCGCTIMER — 16/32-Bit General-Purpose Timer Sleep Mode Clock Gating Control
  [n] SYSCTL_SCGCTIMER_S{n} (n=0..7) — 16/32-Bit General-Purpose Timer {n} Sleep Mode Clock Gating Control
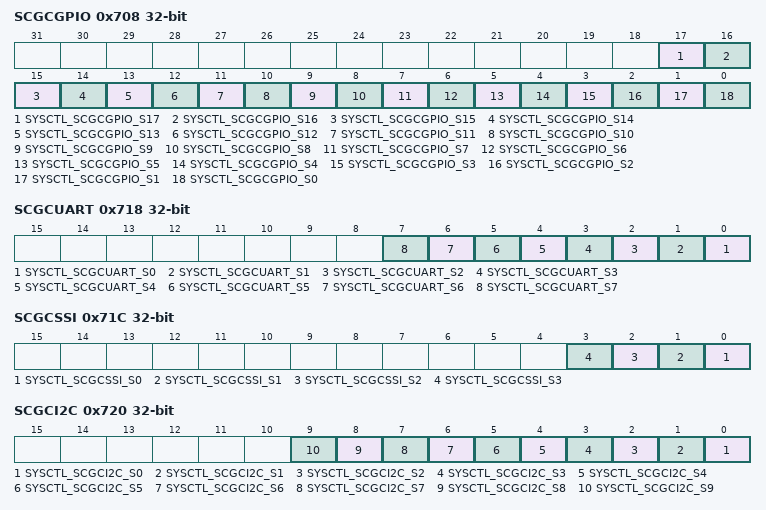
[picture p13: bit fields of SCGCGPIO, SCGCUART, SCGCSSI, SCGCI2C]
0x708 SCGCGPIO — General-Purpose Input/Output Sleep Mode Clock Gating Control
  [17] SYSCTL_SCGCGPIO_S17 — GPIO Port T Sleep Mode Clock Gating Control
  [16] SYSCTL_SCGCGPIO_S16 — GPIO Port S Sleep Mode Clock Gating Control
  [15] SYSCTL_SCGCGPIO_S15 — GPIO Port R Sleep Mode Clock Gating Control
  [14] SYSCTL_SCGCGPIO_S14 — GPIO Port Q Sleep Mode Clock Gating Control
  [13] SYSCTL_SCGCGPIO_S13 — GPIO Port P Sleep Mode Clock Gating Control
  [12] SYSCTL_SCGCGPIO_S12 — GPIO Port N Sleep Mode Clock Gating Control
  [11] SYSCTL_SCGCGPIO_S11 — GPIO Port M Sleep Mode Clock Gating Control
  [10] SYSCTL_SCGCGPIO_S10 — GPIO Port L Sleep Mode Clock Gating Control
  [9] SYSCTL_SCGCGPIO_S9 — GPIO Port K Sleep Mode Clock Gating Control
  [8] SYSCTL_SCGCGPIO_S8 — GPIO Port J Sleep Mode Clock Gating Control
  [7] SYSCTL_SCGCGPIO_S7 — GPIO Port H Sleep Mode Clock Gating Control
  [6] SYSCTL_SCGCGPIO_S6 — GPIO Port G Sleep Mode Clock Gating Control
  [5] SYSCTL_SCGCGPIO_S5 — GPIO Port F Sleep Mode Clock Gating Control
  [4] SYSCTL_SCGCGPIO_S4 — GPIO Port E Sleep Mode Clock Gating Control
  [3] SYSCTL_SCGCGPIO_S3 — GPIO Port D Sleep Mode Clock Gating Control
  [2] SYSCTL_SCGCGPIO_S2 — GPIO Port C Sleep Mode Clock Gating Control
  [1] SYSCTL_SCGCGPIO_S1 — GPIO Port B Sleep Mode Clock Gating Control
  [0] SYSCTL_SCGCGPIO_S0 — GPIO Port A Sleep Mode Clock Gating Control
0x70C SCGCDMA — Micro Direct Memory Access Sleep Mode Clock Gating Control
  [0] SYSCTL_SCGCDMA_S0 — uDMA Module Sleep Mode Clock Gating Control
0x710 SCGCEPI — EPI Sleep Mode Clock Gating Control
  [0] SYSCTL_SCGCEPI_S0 — EPI Module Sleep Mode Clock Gating Control
0x714 SCGCHIB — Hibernation Sleep Mode Clock Gating Control
  [0] SYSCTL_SCGCHIB_S0 — Hibernation Module Sleep Mode Clock Gating Control
0x718 SCGCUART — Universal Asynchronous Receiver/Transmitter Sleep Mode Clock Gating Control
  [n] SYSCTL_SCGCUART_S{n} (n=0..7) — UART Module {n} Sleep Mode Clock Gating Control
0x71C SCGCSSI — Synchronous Serial Interface Sleep Mode Clock Gating Control
  [n] SYSCTL_SCGCSSI_S{n} (n=0..3) — SSI Module {n} Sleep Mode Clock Gating Control
0x720 SCGCI2C — Inter-Integrated Circuit Sleep Mode Clock Gating Control
  [n] SYSCTL_SCGCI2C_S{n} (n=0..9) — I2C Module {n} Sleep Mode Clock Gating Control
0x728 SCGCUSB — Universal Serial Bus Sleep Mode Clock Gating Control
  [0] SYSCTL_SCGCUSB_S0 — USB Module Sleep Mode Clock Gating Control
0x730 SCGCEPHY — Ethernet PHY Sleep Mode Clock Gating Control
  [0] SYSCTL_SCGCEPHY_S0 — PHY Module Sleep Mode Clock Gating Control
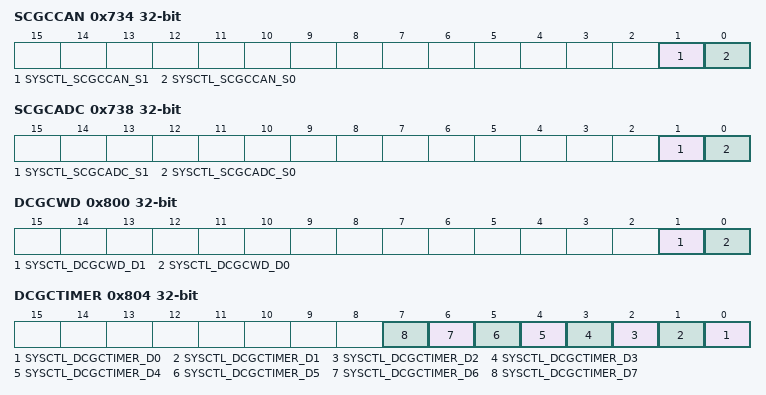
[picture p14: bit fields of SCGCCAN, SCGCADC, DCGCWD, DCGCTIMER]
0x734 SCGCCAN — Controller Area Network Sleep Mode Clock Gating Control
  [1] SYSCTL_SCGCCAN_S1 — CAN Module 1 Sleep Mode Clock Gating Control
  [0] SYSCTL_SCGCCAN_S0 — CAN Module 0 Sleep Mode Clock Gating Control
0x738 SCGCADC — Analog-to-Digital Converter Sleep Mode Clock Gating Control
  [1] SYSCTL_SCGCADC_S1 — ADC Module 1 Sleep Mode Clock Gating Control
  [0] SYSCTL_SCGCADC_S0 — ADC Module 0 Sleep Mode Clock Gating Control
0x73C SCGCACMP — Analog Comparator Sleep Mode Clock Gating Control
  [0] SYSCTL_SCGCACMP_S0 — Analog Comparator Module 0 Sleep Mode Clock Gating Control
0x740 SCGCPWM — Pulse Width Modulator Sleep Mode Clock Gating Control
  [0] SYSCTL_SCGCPWM_S0 — PWM Module 0 Sleep Mode Clock Gating Control
0x744 SCGCQEI — Quadrature Encoder Interface Sleep Mode Clock Gating Control
  [0] SYSCTL_SCGCQEI_S0 — QEI Module 0 Sleep Mode Clock Gating Control
0x758 SCGCEEPROM — EEPROM Sleep Mode Clock Gating Control
  [0] SYSCTL_SCGCEEPROM_S0 — EEPROM Module Sleep Mode Clock Gating Control
0x774 SCGCCCM — CRC and Cryptographic Modules Sleep Mode Clock Gating Control
  [0] SYSCTL_SCGCCCM_S0
0x790 SCGCLCD — LCD Controller Sleep Mode Clock Gating Control
  [0] SYSCTL_SCGCLCD_S0 — LCD Controller Module 0 Sleep Mode Clock Gating Control
0x798 SCGCOWIRE — 1-Wire Sleep Mode Clock Gating Control
  [0] SYSCTL_SCGCOWIRE_S0 — 1-Wire Module 0 Sleep Mode Clock Gating Control
0x79C SCGCEMAC — Ethernet MAC Sleep Mode Clock Gating Control
  [0] SYSCTL_SCGCEMAC_S0 — Ethernet MAC Module 0 Sleep Mode Clock Gating Control
0x800 DCGCWD — Watchdog Timer Deep-Sleep Mode Clock Gating Control
  [1] SYSCTL_DCGCWD_D1 — Watchdog Timer 1 Deep-Sleep Mode Clock Gating Control
  [0] SYSCTL_DCGCWD_D0 — Watchdog Timer 0 Deep-Sleep Mode Clock Gating Control
0x804 DCGCTIMER — 16/32-Bit General-Purpose Timer Deep-Sleep Mode Clock Gating Control
  [n] SYSCTL_DCGCTIMER_D{n} (n=0..7) — 16/32-Bit General-Purpose Timer {n} Deep-Sleep Mode Clock Gating Control
0x808 DCGCGPIO — General-Purpose Input/Output Deep-Sleep Mode Clock Gating Control
  [17] SYSCTL_DCGCGPIO_D17 — GPIO Port T Deep-Sleep Mode Clock Gating Control
  [16] SYSCTL_DCGCGPIO_D16 — GPIO Port S Deep-Sleep Mode Clock Gating Control
  [15] SYSCTL_DCGCGPIO_D15 — GPIO Port R Deep-Sleep Mode Clock Gating Control
  [14] SYSCTL_DCGCGPIO_D14 — GPIO Port Q Deep-Sleep Mode Clock Gating Control
  [13] SYSCTL_DCGCGPIO_D13 — GPIO Port P Deep-Sleep Mode Clock Gating Control
  [12] SYSCTL_DCGCGPIO_D12 — GPIO Port N Deep-Sleep Mode Clock Gating Control
  [11] SYSCTL_DCGCGPIO_D11 — GPIO Port M Deep-Sleep Mode Clock Gating Control
  [10] SYSCTL_DCGCGPIO_D10 — GPIO Port L Deep-Sleep Mode Clock Gating Control
  [9] SYSCTL_DCGCGPIO_D9 — GPIO Port K Deep-Sleep Mode Clock Gating Control
  [8] SYSCTL_DCGCGPIO_D8 — GPIO Port J Deep-Sleep Mode Clock Gating Control
  [7] SYSCTL_DCGCGPIO_D7 — GPIO Port H Deep-Sleep Mode Clock Gating Control
  [6] SYSCTL_DCGCGPIO_D6 — GPIO Port G Deep-Sleep Mode Clock Gating Control
  [5] SYSCTL_DCGCGPIO_D5 — GPIO Port F Deep-Sleep Mode Clock Gating Control
  [4] SYSCTL_DCGCGPIO_D4 — GPIO Port E Deep-Sleep Mode Clock Gating Control
  [3] SYSCTL_DCGCGPIO_D3 — GPIO Port D Deep-Sleep Mode Clock Gating Control
  [2] SYSCTL_DCGCGPIO_D2 — GPIO Port C Deep-Sleep Mode Clock Gating Control
  [1] SYSCTL_DCGCGPIO_D1 — GPIO Port B Deep-Sleep Mode Clock Gating Control
  [0] SYSCTL_DCGCGPIO_D0 — GPIO Port A Deep-Sleep Mode Clock Gating Control
0x80C DCGCDMA — Micro Direct Memory Access Deep-Sleep Mode Clock Gating Control
  [0] SYSCTL_DCGCDMA_D0 — uDMA Module Deep-Sleep Mode Clock Gating Control
0x810 DCGCEPI — EPI Deep-Sleep Mode Clock Gating Control
  [0] SYSCTL_DCGCEPI_D0 — EPI Module Deep-Sleep Mode Clock Gating Control
0x814 DCGCHIB — Hibernation Deep-Sleep Mode Clock Gating Control
  [0] SYSCTL_DCGCHIB_D0 — Hibernation Module Deep-Sleep Mode Clock Gating Control
0x818 DCGCUART — Universal Asynchronous Receiver/Transmitter Deep-Sleep Mode Clock Gating Control
  [n] SYSCTL_DCGCUART_D{n} (n=0..7) — UART Module {n} Deep-Sleep Mode Clock Gating Control
0x81C DCGCSSI — Synchronous Serial Interface Deep-Sleep Mode Clock Gating Control
  [n] SYSCTL_DCGCSSI_D{n} (n=0..3) — SSI Module {n} Deep-Sleep Mode Clock Gating Control
0x820 DCGCI2C — Inter-Integrated Circuit Deep-Sleep Mode Clock Gating Control
  [n] SYSCTL_DCGCI2C_D{n} (n=0..9) — I2C Module {n} Deep-Sleep Mode Clock Gating Control
0x828 DCGCUSB — Universal Serial Bus Deep-Sleep Mode Clock Gating Control
  [0] SYSCTL_DCGCUSB_D0 — USB Module Deep-Sleep Mode Clock Gating Control
0x830 DCGCEPHY — Ethernet PHY Deep-Sleep Mode Clock Gating Control
  [0] SYSCTL_DCGCEPHY_D0 — PHY Module Deep-Sleep Mode Clock Gating Control
0x834 DCGCCAN — Controller Area Network Deep-Sleep Mode Clock Gating Control
  [1] SYSCTL_DCGCCAN_D1 — CAN Module 1 Deep-Sleep Mode Clock Gating Control
  [0] SYSCTL_DCGCCAN_D0 — CAN Module 0 Deep-Sleep Mode Clock Gating Control
0x838 DCGCADC — Analog-to-Digital Converter Deep-Sleep Mode Clock Gating Control
  [1] SYSCTL_DCGCADC_D1 — ADC Module 1 Deep-Sleep Mode Clock Gating Control
  [0] SYSCTL_DCGCADC_D0 — ADC Module 0 Deep-Sleep Mode Clock Gating Control
0x83C DCGCACMP — Analog Comparator Deep-Sleep Mode Clock Gating Control
  [0] SYSCTL_DCGCACMP_D0 — Analog Comparator Module 0 Deep-Sleep Mode Clock Gating Control
0x840 DCGCPWM — Pulse Width Modulator Deep-Sleep Mode Clock Gating Control
  [0] SYSCTL_DCGCPWM_D0 — PWM Module 0 Deep-Sleep Mode Clock Gating Control
0x844 DCGCQEI — Quadrature Encoder Interface Deep-Sleep Mode Clock Gating Control
  [0] SYSCTL_DCGCQEI_D0 — QEI Module 0 Deep-Sleep Mode Clock Gating Control
0x858 DCGCEEPROM — EEPROM Deep-Sleep Mode Clock Gating Control
  [0] SYSCTL_DCGCEEPROM_D0 — EEPROM Module Deep-Sleep Mode Clock Gating Control
0x874 DCGCCCM — CRC and Cryptographic Modules Deep-Sleep Mode Clock Gating Control
  [0] SYSCTL_DCGCCCM_D0
0x890 DCGCLCD — LCD Controller Deep-Sleep Mode Clock Gating Control
  [0] SYSCTL_DCGCLCD_D0 — LCD Controller Module 0 Deep-Sleep Mode Clock Gating Control
0x898 DCGCOWIRE — 1-Wire Deep-Sleep Mode Clock Gating Control
  [0] SYSCTL_DCGCOWIRE_D0 — 1-Wire Module 0 Deep-Sleep Mode Clock Gating Control
0x89C DCGCEMAC — Ethernet MAC Deep-Sleep Mode Clock Gating Control
  [0] SYSCTL_DCGCEMAC_D0 — Ethernet MAC Module 0 Deep-Sleep Mode Clock Gating Control
0x900 PCWD — Watchdog Timer Power Control
  [1] SYSCTL_PCWD_P1 — Watchdog Timer 1 Power Control
  [0] SYSCTL_PCWD_P0 — Watchdog Timer 0 Power Control
0x904 PCTIMER — 16/32-Bit General-Purpose Timer Power Control
  [n] SYSCTL_PCTIMER_P{n} (n=0..7) — General-Purpose Timer {n} Power Control
0x908 PCGPIO — General-Purpose Input/Output Power Control
  [17] SYSCTL_PCGPIO_P17 — GPIO Port T Power Control
  [16] SYSCTL_PCGPIO_P16 — GPIO Port S Power Control
  [15] SYSCTL_PCGPIO_P15 — GPIO Port R Power Control
  [14] SYSCTL_PCGPIO_P14 — GPIO Port Q Power Control
  [13] SYSCTL_PCGPIO_P13 — GPIO Port P Power Control
  [12] SYSCTL_PCGPIO_P12 — GPIO Port N Power Control
  [11] SYSCTL_PCGPIO_P11 — GPIO Port M Power Control
  [10] SYSCTL_PCGPIO_P10 — GPIO Port L Power Control
  [9] SYSCTL_PCGPIO_P9 — GPIO Port K Power Control
  [8] SYSCTL_PCGPIO_P8 — GPIO Port J Power Control
  [7] SYSCTL_PCGPIO_P7 — GPIO Port H Power Control
  [6] SYSCTL_PCGPIO_P6 — GPIO Port G Power Control
  [5] SYSCTL_PCGPIO_P5 — GPIO Port F Power Control
  [4] SYSCTL_PCGPIO_P4 — GPIO Port E Power Control
  [3] SYSCTL_PCGPIO_P3 — GPIO Port D Power Control
  [2] SYSCTL_PCGPIO_P2 — GPIO Port C Power Control
  [1] SYSCTL_PCGPIO_P1 — GPIO Port B Power Control
  [0] SYSCTL_PCGPIO_P0 — GPIO Port A Power Control
0x90C PCDMA — Micro Direct Memory Access Power Control
  [0] SYSCTL_PCDMA_P0 — uDMA Module Power Control
0x910 PCEPI — External Peripheral Interface Power Control
  [0] SYSCTL_PCEPI_P0 — EPI Module Power Control
0x914 PCHIB — Hibernation Power Control
  [0] SYSCTL_PCHIB_P0 — Hibernation Module Power Control
0x918 PCUART — Universal Asynchronous Receiver/Transmitter Power Control
  [n] SYSCTL_PCUART_P{n} (n=0..7) — UART Module {n} Power Control
0x91C PCSSI — Synchronous Serial Interface Power Control
  [n] SYSCTL_PCSSI_P{n} (n=0..3) — SSI Module {n} Power Control
0x920 PCI2C — Inter-Integrated Circuit Power Control
  [n] SYSCTL_PCI2C_P{n} (n=0..9) — I2C Module {n} Power Control
0x928 PCUSB — Universal Serial Bus Power Control
  [0] SYSCTL_PCUSB_P0 — USB Module Power Control
0x930 PCEPHY — Ethernet PHY Power Control
  [0] SYSCTL_PCEPHY_P0 — Ethernet PHY Module Power Control
0x934 PCCAN — Controller Area Network Power Control
  [1] SYSCTL_PCCAN_P1 — CAN Module 1 Power Control
  [0] SYSCTL_PCCAN_P0 — CAN Module 0 Power Control
0x938 PCADC — Analog-to-Digital Converter Power Control
  [1] SYSCTL_PCADC_P1 — ADC Module 1 Power Control
  [0] SYSCTL_PCADC_P0 — ADC Module 0 Power Control
0x93C PCACMP — Analog Comparator Power Control
  [0] SYSCTL_PCACMP_P0 — Analog Comparator Module 0 Power Control
0x940 PCPWM — Pulse Width Modulator Power Control
  [0] SYSCTL_PCPWM_P0 — PWM Module 0 Power Control
0x944 PCQEI — Quadrature Encoder Interface Power Control
  [0] SYSCTL_PCQEI_P0 — QEI Module 0 Power Control
0x958 PCEEPROM — EEPROM Power Control
  [0] SYSCTL_PCEEPROM_P0 — EEPROM Module 0 Power Control
0x974 PCCCM — CRC and Cryptographic Modules Power Control
  [0] SYSCTL_PCCCM_P0
0x990 PCLCD — LCD Controller Power Control
  [0] SYSCTL_PCLCD_P0 — LCD Controller Module 0 Power Control
0x998 PCOWIRE — 1-Wire Power Control
  [0] SYSCTL_PCOWIRE_P0 — 1-Wire Module 0 Power Control
0x99C PCEMAC — Ethernet MAC Power Control
  [0] SYSCTL_PCEMAC_P0 — Ethernet MAC Module 0 Power Control
0xA00 PRWD — Watchdog Timer Peripheral Ready
  [1] SYSCTL_PRWD_R1 — Watchdog Timer 1 Peripheral Ready
  [0] SYSCTL_PRWD_R0 — Watchdog Timer 0 Peripheral Ready
0xA04 PRTIMER — 16/32-Bit General-Purpose Timer Peripheral Ready
  [n] SYSCTL_PRTIMER_R{n} (n=0..7) — 16/32-Bit General-Purpose Timer {n} Peripheral Ready
0xA08 PRGPIO — General-Purpose Input/Output Peripheral Ready
  [17] SYSCTL_PRGPIO_R17 — GPIO Port T Peripheral Ready
  [16] SYSCTL_PRGPIO_R16 — GPIO Port S Peripheral Ready
  [15] SYSCTL_PRGPIO_R15 — GPIO Port R Peripheral Ready
  [14] SYSCTL_PRGPIO_R14 — GPIO Port Q Peripheral Ready
  [13] SYSCTL_PRGPIO_R13 — GPIO Port P Peripheral Ready
  [12] SYSCTL_PRGPIO_R12 — GPIO Port N Peripheral Ready
  [11] SYSCTL_PRGPIO_R11 — GPIO Port M Peripheral Ready
  [10] SYSCTL_PRGPIO_R10 — GPIO Port L Peripheral Ready
  [9] SYSCTL_PRGPIO_R9 — GPIO Port K Peripheral Ready
  [8] SYSCTL_PRGPIO_R8 — GPIO Port J Peripheral Ready
  [7] SYSCTL_PRGPIO_R7 — GPIO Port H Peripheral Ready
  [6] SYSCTL_PRGPIO_R6 — GPIO Port G Peripheral Ready
  [5] SYSCTL_PRGPIO_R5 — GPIO Port F Peripheral Ready
  [4] SYSCTL_PRGPIO_R4 — GPIO Port E Peripheral Ready
  [3] SYSCTL_PRGPIO_R3 — GPIO Port D Peripheral Ready
  [2] SYSCTL_PRGPIO_R2 — GPIO Port C Peripheral Ready
  [1] SYSCTL_PRGPIO_R1 — GPIO Port B Peripheral Ready
  [0] SYSCTL_PRGPIO_R0 — GPIO Port A Peripheral Ready
0xA0C PRDMA — Micro Direct Memory Access Peripheral Ready
  [0] SYSCTL_PRDMA_R0 — uDMA Module Peripheral Ready
0xA10 PREPI — EPI Peripheral Ready
  [0] SYSCTL_PREPI_R0 — EPI Module Peripheral Ready
0xA14 PRHIB — Hibernation Peripheral Ready
  [0] SYSCTL_PRHIB_R0 — Hibernation Module Peripheral Ready
0xA18 PRUART — Universal Asynchronous Receiver/Transmitter Peripheral Ready
  [n] SYSCTL_PRUART_R{n} (n=0..7) — UART Module {n} Peripheral Ready
0xA1C PRSSI — Synchronous Serial Interface Peripheral Ready
  [n] SYSCTL_PRSSI_R{n} (n=0..3) — SSI Module {n} Peripheral Ready
0xA20 PRI2C — Inter-Integrated Circuit Peripheral Ready
  [n] SYSCTL_PRI2C_R{n} (n=0..9) — I2C Module {n} Peripheral Ready
0xA28 PRUSB — Universal Serial Bus Peripheral Ready
  [0] SYSCTL_PRUSB_R0 — USB Module Peripheral Ready
0xA30 PREPHY — Ethernet PHY Peripheral Ready
  [0] SYSCTL_PREPHY_R0 — Ethernet PHY Module Peripheral Ready
0xA34 PRCAN — Controller Area Network Peripheral Ready
  [1] SYSCTL_PRCAN_R1 — CAN Module 1 Peripheral Ready
  [0] SYSCTL_PRCAN_R0 — CAN Module 0 Peripheral Ready
0xA38 PRADC — Analog-to-Digital Converter Peripheral Ready
  [1] SYSCTL_PRADC_R1 — ADC Module 1 Peripheral Ready
  [0] SYSCTL_PRADC_R0 — ADC Module 0 Peripheral Ready
0xA3C PRACMP — Analog Comparator Peripheral Ready
  [0] SYSCTL_PRACMP_R0 — Analog Comparator Module 0 Peripheral Ready
0xA40 PRPWM — Pulse Width Modulator Peripheral Ready
  [0] SYSCTL_PRPWM_R0 — PWM Module 0 Peripheral Ready
0xA44 PRQEI — Quadrature Encoder Interface Peripheral Ready
  [0] SYSCTL_PRQEI_R0 — QEI Module 0 Peripheral Ready
0xA58 PREEPROM — EEPROM Peripheral Ready
  [0] SYSCTL_PREEPROM_R0 — EEPROM Module Peripheral Ready
0xA74 PRCCM — CRC and Cryptographic Modules Peripheral Ready
  [0] SYSCTL_PRCCM_R0
0xA90 PRLCD — LCD Controller Peripheral Ready
  [0] SYSCTL_PRLCD_R0 — LCD Controller Module 0 Peripheral Ready
0xA98 PROWIRE — 1-Wire Peripheral Ready
  [0] SYSCTL_PROWIRE_R0 — 1-Wire Module 0 Peripheral Ready
0xA9C PREMAC — Ethernet MAC Peripheral Ready
  [0] SYSCTL_PREMAC_R0 — Ethernet MAC Module 0 Peripheral Ready

## Notices in the file
Software License Agreement
Texas Instruments (TI) is supplying this software for use solely and
exclusively on TI's microcontroller products. The software is owned by
TI and/or its suppliers, and is protected under applicable copyright
laws. You may not combine this software with "viral" open-source
software in order to form a larger program.
THIS SOFTWARE IS PROVIDED "AS IS" AND WITH ALL FAULTS.
NO WARRANTIES, WHETHER EXPRESS, IMPLIED OR STATUTORY, INCLUDING, BUT
NOT LIMITED TO, IMPLIED WARRANTIES OF MERCHANTABILITY AND FITNESS FOR
A PARTICULAR PURPOSE APPLY TO THIS SOFTWARE. TI SHALL NOT, UNDER ANY
CIRCUMSTANCES, BE LIABLE FOR SPECIAL, INCIDENTAL, OR CONSEQUENTIAL
DAMAGES, FOR ANY REASON WHATSOEVER.
